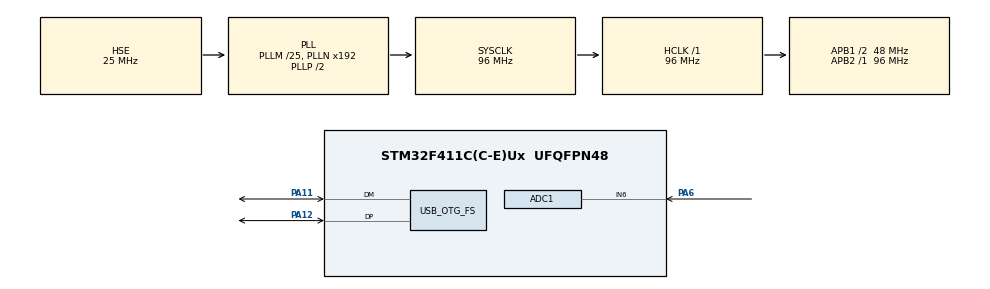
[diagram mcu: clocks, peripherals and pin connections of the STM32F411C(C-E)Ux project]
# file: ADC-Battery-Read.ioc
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ADC1.Channel-2\#ChannelRegularConversion=ADC_CHANNEL_6
ADC1.ClockPrescaler=ADC_CLOCK_SYNC_PCLK_DIV4
ADC1.ContinuousConvMode=DISABLE
ADC1.DMAContinuousRequests=DISABLE
ADC1.ExternalTrigConv=ADC_EXTERNALTRIGCONV_T3_TRGO
ADC1.NbrOfConversionFlag=1
ADC1.Rank-2\#ChannelRegularConversion=1
ADC1.SamplingTime-2\#ChannelRegularConversion=ADC_SAMPLETIME_3CYCLES
ADC1.master=1
Mcu.Family=STM32F4
Mcu.Name=STM32F411C(C-E)Ux
Mcu.Package=UFQFPN48
NVIC.ADC_IRQn=true\:0\:0\:false\:false\:true\:true\:true\:true
NVIC.OTG_FS_IRQn=true\:0\:0\:false\:false\:true\:false\:true\:true
NVIC.PriorityGroup=NVIC_PRIORITYGROUP_4
PA11.Mode=Device_Only
PA11.Signal=USB_OTG_FS_DM
PA12.Mode=Device_Only
PA12.Signal=USB_OTG_FS_DP
PA6.Signal=ADCx_IN6
PC14-OSC32_IN.Mode=LSE-External-Oscillator
PC14-OSC32_IN.Signal=RCC_OSC32_IN
PC15-OSC32_OUT.Mode=LSE-External-Oscillator
PC15-OSC32_OUT.Signal=RCC_OSC32_OUT
PH0\ -\ OSC_IN.Mode=HSE-External-Oscillator
PH0\ -\ OSC_IN.Signal=RCC_OSC_IN
PH1\ -\ OSC_OUT.Mode=HSE-External-Oscillator
PH1\ -\ OSC_OUT.Signal=RCC_OSC_OUT
ProjectManager.HeapSize=0x200
ProjectManager.StackSize=0x400
ProjectManager.TargetToolchain=Makefile
RCC.48MHZClocksFreq_Value=48000000
RCC.AHBFreq_Value=96000000
RCC.APB1CLKDivider=RCC_HCLK_DIV2
RCC.APB1Freq_Value=48000000
RCC.APB1TimFreq_Value=96000000
RCC.APB2Freq_Value=96000000
RCC.APB2TimFreq_Value=96000000
RCC.CortexFreq_Value=96000000
RCC.HCLKFreq_Value=96000000
RCC.HSE_VALUE=25000000
RCC.HSI_VALUE=16000000
RCC.PLLM=25
RCC.PLLSourceVirtual=RCC_PLLSOURCE_HSE
RCC.SYSCLKFreq_VALUE=96000000
RCC.SYSCLKSource=RCC_SYSCLKSOURCE_PLLCLK
RCC.VCOOutputFreq_Value=192000000
SH.ADCx_IN6.0=ADC1_IN6,IN6
TIM3.Channel-PWM\ Generation1\ No\ Output=TIM_CHANNEL_1
TIM3.Period=100-1
TIM3.Prescaler=9600-1
TIM3.TIM_MasterOutputTrigger=TIM_TRGO_UPDATE
USB_DEVICE.CLASS_NAME_FS=CDC
USB_DEVICE.VirtualMode=Cdc
USB_DEVICE.VirtualModeFS=Cdc_FS
USB_OTG_FS.VirtualMode=Device_Only
VP_TIM3_VS_ClockSourceINT.Mode=Internal
VP_TIM3_VS_no_output1.Mode=PWM Generation1 No Output
VP_USB_DEVICE_VS_USB_DEVICE_CDC_FS.Mode=CDC_FS
board=custom

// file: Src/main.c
/* USER CODE BEGIN Header */
/**
  ******************************************************************************
  * @file           : main.c
  * @brief          : Main program body
  ******************************************************************************
  * @attention
  *
  * Copyright (c) 2022 STMicroelectronics.
  * All rights reserved.
  *
  * This software is licensed under terms that can be found in the LICENSE file
  * in the root directory of this software component.
  * If no LICENSE file comes with this software, it is provided AS-IS.
  *
  ******************************************************************************
  */
/* USER CODE END Header */
#include "main.h"
#include "usb_device.h"

ADC_HandleTypeDef hadc1;

TIM_HandleTypeDef htim3;

void SystemClock_Config(void);
static void MX_GPIO_Init(void);
static void MX_ADC1_Init(void);
static void MX_TIM3_Init(void);
/* USER CODE BEGIN PFP */

extern uint8_t CDC_Transmit_FS(uint8_t* Buf, uint16_t Len);

/* USER CODE END PFP */

/* USER CODE BEGIN 0 */

Battery bat;

int _write(int file, char *ptr, int len)
{
    UNUSED(file);
    CDC_Transmit_FS((uint8_t*)ptr, len);
    return len;
}

void HAL_ADC_ConvCpltCallback(ADC_HandleTypeDef *hadc)
{
  BatteryADCIRQ(hadc, &bat);
}

/* USER CODE END 0 */

int main(void)
{

  /* MCU Configuration--------------------------------------------------------*/

  /* Reset of all peripherals, Initializes the Flash interface and the Systick. */
  HAL_Init();

  /* Configure the system clock */
  SystemClock_Config();

  /* Initialize all configured peripherals */
  MX_GPIO_Init();
  MX_ADC1_Init();
  MX_USB_DEVICE_Init();
  MX_TIM3_Init();
  /* USER CODE BEGIN 2 */

  HAL_TIM_PWM_Start(&htim3, TIM_CHANNEL_1);

  // HAL_ADC_Start_IT(&hadc1);
  __HAL_TIM_CLEAR_FLAG(&htim3, TIM_FLAG_UPDATE);
  HAL_ADC_Start_IT(&hadc1);

  bat.resistor_one = 100000;
  bat.resistor_two = 22000;

  /* USER CODE END 2 */

  /* Infinite loop */
  /* USER CODE BEGIN WHILE */
  while (1)
  {
    printf("%f\n", bat.voltage);
    // HAL_ADC_Start_IT(&hadc1);
    // printf("%d\n", adc_buf[0]);
    HAL_Delay(500);
    /* USER CODE END WHILE */

  }
}

void SystemClock_Config(void)
{
  RCC_OscInitTypeDef RCC_OscInitStruct = {0};
  RCC_ClkInitTypeDef RCC_ClkInitStruct = {0};

  /** Configure the main internal regulator output voltage
  */
  __HAL_RCC_PWR_CLK_ENABLE();
  __HAL_PWR_VOLTAGESCALING_CONFIG(PWR_REGULATOR_VOLTAGE_SCALE1);

  /** Initializes the RCC Oscillators according to the specified parameters
  * in the RCC_OscInitTypeDef structure.
  */
  RCC_OscInitStruct.OscillatorType = RCC_OSCILLATORTYPE_HSE;
  RCC_OscInitStruct.HSEState = RCC_HSE_ON;
  RCC_OscInitStruct.PLL.PLLState = RCC_PLL_ON;
  RCC_OscInitStruct.PLL.PLLSource = RCC_PLLSOURCE_HSE;
  RCC_OscInitStruct.PLL.PLLM = 25;
  RCC_OscInitStruct.PLL.PLLN = 192;
  RCC_OscInitStruct.PLL.PLLP = RCC_PLLP_DIV2;
  RCC_OscInitStruct.PLL.PLLQ = 4;
  if (HAL_RCC_OscConfig(&RCC_OscInitStruct) != HAL_OK)
  {
    Error_Handler();
  }

  /** Initializes the CPU, AHB and APB buses clocks
  */
  RCC_ClkInitStruct.ClockType = RCC_CLOCKTYPE_HCLK|RCC_CLOCKTYPE_SYSCLK
                              |RCC_CLOCKTYPE_PCLK1|RCC_CLOCKTYPE_PCLK2;
  RCC_ClkInitStruct.SYSCLKSource = RCC_SYSCLKSOURCE_PLLCLK;
  RCC_ClkInitStruct.AHBCLKDivider = RCC_SYSCLK_DIV1;
  RCC_ClkInitStruct.APB1CLKDivider = RCC_HCLK_DIV2;
  RCC_ClkInitStruct.APB2CLKDivider = RCC_HCLK_DIV1;

  if (HAL_RCC_ClockConfig(&RCC_ClkInitStruct, FLASH_LATENCY_3) != HAL_OK)
  {
    Error_Handler();
  }
}

static void MX_ADC1_Init(void)
{

  ADC_ChannelConfTypeDef sConfig = {0};

  /** Configure the global features of the ADC (Clock, Resolution, Data Alignment and number of conversion)
  */
  hadc1.Instance = ADC1;
  hadc1.Init.ClockPrescaler = ADC_CLOCK_SYNC_PCLK_DIV4;
  hadc1.Init.Resolution = ADC_RESOLUTION_12B;
  hadc1.Init.ScanConvMode = DISABLE;
  hadc1.Init.ContinuousConvMode = DISABLE;
  hadc1.Init.DiscontinuousConvMode = DISABLE;
  hadc1.Init.ExternalTrigConvEdge = ADC_EXTERNALTRIGCONVEDGE_RISING;
  hadc1.Init.ExternalTrigConv = ADC_EXTERNALTRIGCONV_T3_TRGO;
  hadc1.Init.DataAlign = ADC_DATAALIGN_RIGHT;
  hadc1.Init.NbrOfConversion = 1;
  hadc1.Init.DMAContinuousRequests = DISABLE;
  hadc1.Init.EOCSelection = ADC_EOC_SINGLE_CONV;
  if (HAL_ADC_Init(&hadc1) != HAL_OK)
  {
    Error_Handler();
  }

  /** Configure for the selected ADC regular channel its corresponding rank in the sequencer and its sample time.
  */
  sConfig.Channel = ADC_CHANNEL_6;
  sConfig.Rank = 1;
  sConfig.SamplingTime = ADC_SAMPLETIME_3CYCLES;
  if (HAL_ADC_ConfigChannel(&hadc1, &sConfig) != HAL_OK)
  {
    Error_Handler();
  }

}

static void MX_TIM3_Init(void)
{

  TIM_ClockConfigTypeDef sClockSourceConfig = {0};
  TIM_MasterConfigTypeDef sMasterConfig = {0};
  TIM_OC_InitTypeDef sConfigOC = {0};

  htim3.Instance = TIM3;
  htim3.Init.Prescaler = 9600-1;
  htim3.Init.CounterMode = TIM_COUNTERMODE_UP;
  htim3.Init.Period = 100-1;
  htim3.Init.ClockDivision = TIM_CLOCKDIVISION_DIV1;
  htim3.Init.AutoReloadPreload = TIM_AUTORELOAD_PRELOAD_DISABLE;
  if (HAL_TIM_Base_Init(&htim3) != HAL_OK)
  {
    Error_Handler();
  }
  sClockSourceConfig.ClockSource = TIM_CLOCKSOURCE_INTERNAL;
  if (HAL_TIM_ConfigClockSource(&htim3, &sClockSourceConfig) != HAL_OK)
  {
    Error_Handler();
  }
  if (HAL_TIM_PWM_Init(&htim3) != HAL_OK)
  {
    Error_Handler();
  }
  sMasterConfig.MasterOutputTrigger = TIM_TRGO_UPDATE;
  sMasterConfig.MasterSlaveMode = TIM_MASTERSLAVEMODE_DISABLE;
  if (HAL_TIMEx_MasterConfigSynchronization(&htim3, &sMasterConfig) != HAL_OK)
  {
    Error_Handler();
  }
  sConfigOC.OCMode = TIM_OCMODE_PWM1;
  sConfigOC.Pulse = 0;
  sConfigOC.OCPolarity = TIM_OCPOLARITY_HIGH;
  sConfigOC.OCFastMode = TIM_OCFAST_DISABLE;
  if (HAL_TIM_PWM_ConfigChannel(&htim3, &sConfigOC, TIM_CHANNEL_1) != HAL_OK)
  {
    Error_Handler();
  }

}

static void MX_GPIO_Init(void)
{

  /* GPIO Ports Clock Enable */
  __HAL_RCC_GPIOC_CLK_ENABLE();
  __HAL_RCC_GPIOH_CLK_ENABLE();
  __HAL_RCC_GPIOA_CLK_ENABLE();

}

void Error_Handler(void)
{
  /* USER CODE BEGIN Error_Handler_Debug */
  /* User can add his own implementation to report the HAL error return state */
  __disable_irq();
  printf("ERROR\n");
  while (1)
  {
  }
  /* USER CODE END Error_Handler_Debug */
}
